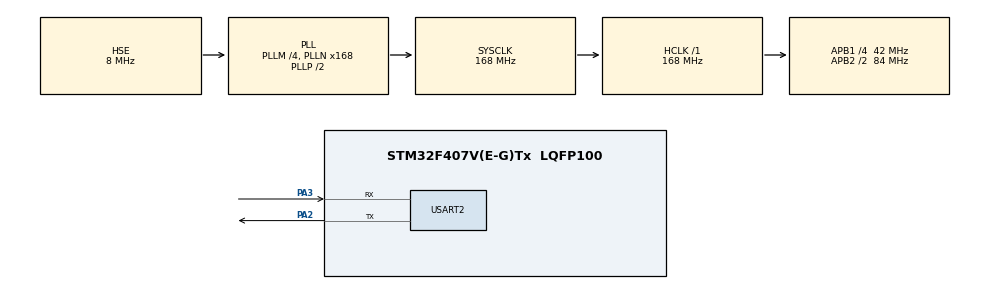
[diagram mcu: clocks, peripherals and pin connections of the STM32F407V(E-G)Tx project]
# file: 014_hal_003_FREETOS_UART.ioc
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FREERTOS.Tasks01=defaultTask,0,128,StartDefaultTask,Default,NULL,Dynamic,NULL,NULL;myTask02,0,128,StartTask02,Default,NULL,Dynamic,NULL,NULL
FREERTOS.configUSE_NEWLIB_REENTRANT=1
Mcu.Family=STM32F4
Mcu.Name=STM32F407V(E-G)Tx
Mcu.Package=LQFP100
NVIC.PriorityGroup=NVIC_PRIORITYGROUP_4
NVIC.TIM2_IRQn=true\:15\:0\:false\:false\:true\:false\:false\:true\:true
NVIC.TimeBase=TIM2_IRQn
NVIC.TimeBaseIP=TIM2
PA2.Mode=Asynchronous
PA2.Signal=USART2_TX
PA3.Mode=Asynchronous
PA3.Signal=USART2_RX
PH0-OSC_IN.Mode=HSE-External-Oscillator
PH0-OSC_IN.Signal=RCC_OSC_IN
PH1-OSC_OUT.Mode=HSE-External-Oscillator
PH1-OSC_OUT.Signal=RCC_OSC_OUT
ProjectManager.HeapSize=0x200
ProjectManager.StackSize=0x400
ProjectManager.TargetToolchain=STM32CubeIDE
RCC.48MHZClocksFreq_Value=84000000
RCC.AHBFreq_Value=168000000
RCC.APB1CLKDivider=RCC_HCLK_DIV4
RCC.APB1Freq_Value=42000000
RCC.APB1TimFreq_Value=84000000
RCC.APB2CLKDivider=RCC_HCLK_DIV2
RCC.APB2Freq_Value=84000000
RCC.APB2TimFreq_Value=168000000
RCC.CortexFreq_Value=168000000
RCC.HCLKFreq_Value=168000000
RCC.HSE_VALUE=8000000
RCC.HSI_VALUE=16000000
RCC.LSE_VALUE=32768
RCC.PLLM=4
RCC.PLLN=168
RCC.PLLSourceVirtual=RCC_PLLSOURCE_HSE
RCC.SYSCLKFreq_VALUE=168000000
RCC.SYSCLKSource=RCC_SYSCLKSOURCE_PLLCLK
RCC.VCOOutputFreq_Value=336000000
USART2.VirtualMode=VM_ASYNC
VP_FREERTOS_VS_CMSIS_V1.Mode=CMSIS_V1
VP_SYS_VS_tim2.Mode=TIM2
board=custom

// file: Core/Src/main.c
/* USER CODE BEGIN Header */
/**
  ******************************************************************************
  * @file           : main.c
  * @brief          : Main program body
  ******************************************************************************
  * @attention
  *
  * Copyright (c) 2023 STMicroelectronics.
  * All rights reserved.
  *
  * This software is licensed under terms that can be found in the LICENSE file
  * in the root directory of this software component.
  * If no LICENSE file comes with this software, it is provided AS-IS.
  *
  ******************************************************************************
  */
/* USER CODE END Header */
#include "main.h"
#include "cmsis_os.h"

UART_HandleTypeDef huart2;

osThreadId defaultTaskHandle;
osThreadId myTask02Handle;

/* USER CODE BEGIN PV */

osThreadId Task3Handle;

/* USER CODE END PV */

void SystemClock_Config(void);
static void MX_GPIO_Init(void);
static void MX_USART2_UART_Init(void);
void StartDefaultTask(void const * argument);
void StartTask02(void const * argument);

/* USER CODE BEGIN PFP */

void Task3_init(void const * argument);

/* USER CODE END PFP */

/* USER CODE BEGIN 0 */

void send_deftask(void){
	uint8_t data[]="hello from send_deftask.\n";
	HAL_UART_Transmit(&huart2, data, sizeof(data), 500);
}

void send_task2(void){
	uint8_t data[]="hello from send_task2.\n";
	HAL_UART_Transmit(&huart2, data, sizeof(data), 500);
}

void send_task3(void){
	uint8_t data[]="hello from send_task3.\n";
	HAL_UART_Transmit(&huart2, data, sizeof(data), 500);
}

/* USER CODE END 0 */

int main(void)
{

  /* MCU Configuration--------------------------------------------------------*/

  /* Reset of all peripherals, Initializes the Flash interface and the Systick. */
  HAL_Init();

  /* Configure the system clock */
  SystemClock_Config();

  /* Initialize all configured peripherals */
  MX_GPIO_Init();
  MX_USART2_UART_Init();

  /* Create the thread(s) */
  /* definition and creation of defaultTask */
  osThreadDef(defaultTask, StartDefaultTask, osPriorityNormal, 0, 128);
  defaultTaskHandle = osThreadCreate(osThread(defaultTask), NULL);

  /* definition and creation of myTask02 */
  osThreadDef(myTask02, StartTask02, osPriorityAboveNormal, 0, 128);
  myTask02Handle = osThreadCreate(osThread(myTask02), NULL);

  /* USER CODE BEGIN RTOS_THREADS */
  /* add threads, ... */

  osThreadDef(Task3,Task3_init,osPriorityBelowNormal,0,128);
  Task3Handle = osThreadCreate(osThread(Task3),NULL);

  /* USER CODE END RTOS_THREADS */

  /* Start scheduler */
  osKernelStart();
  /* We should never get here as control is now taken by the scheduler */
  /* Infinite loop */
  while (1)
  {

  }
}

void SystemClock_Config(void)
{
  RCC_OscInitTypeDef RCC_OscInitStruct = {0};
  RCC_ClkInitTypeDef RCC_ClkInitStruct = {0};

  /** Configure the main internal regulator output voltage
  */
  __HAL_RCC_PWR_CLK_ENABLE();
  __HAL_PWR_VOLTAGESCALING_CONFIG(PWR_REGULATOR_VOLTAGE_SCALE1);

  /** Initializes the RCC Oscillators according to the specified parameters
  * in the RCC_OscInitTypeDef structure.
  */
  RCC_OscInitStruct.OscillatorType = RCC_OSCILLATORTYPE_HSE;
  RCC_OscInitStruct.HSEState = RCC_HSE_ON;
  RCC_OscInitStruct.PLL.PLLState = RCC_PLL_ON;
  RCC_OscInitStruct.PLL.PLLSource = RCC_PLLSOURCE_HSE;
  RCC_OscInitStruct.PLL.PLLM = 4;
  RCC_OscInitStruct.PLL.PLLN = 168;
  RCC_OscInitStruct.PLL.PLLP = RCC_PLLP_DIV2;
  RCC_OscInitStruct.PLL.PLLQ = 4;
  if (HAL_RCC_OscConfig(&RCC_OscInitStruct) != HAL_OK)
  {
    Error_Handler();
  }

  /** Initializes the CPU, AHB and APB buses clocks
  */
  RCC_ClkInitStruct.ClockType = RCC_CLOCKTYPE_HCLK|RCC_CLOCKTYPE_SYSCLK
                              |RCC_CLOCKTYPE_PCLK1|RCC_CLOCKTYPE_PCLK2;
  RCC_ClkInitStruct.SYSCLKSource = RCC_SYSCLKSOURCE_PLLCLK;
  RCC_ClkInitStruct.AHBCLKDivider = RCC_SYSCLK_DIV1;
  RCC_ClkInitStruct.APB1CLKDivider = RCC_HCLK_DIV4;
  RCC_ClkInitStruct.APB2CLKDivider = RCC_HCLK_DIV2;

  if (HAL_RCC_ClockConfig(&RCC_ClkInitStruct, FLASH_LATENCY_5) != HAL_OK)
  {
    Error_Handler();
  }
}

static void MX_USART2_UART_Init(void)
{

  huart2.Instance = USART2;
  huart2.Init.BaudRate = 115200;
  huart2.Init.WordLength = UART_WORDLENGTH_8B;
  huart2.Init.StopBits = UART_STOPBITS_1;
  huart2.Init.Parity = UART_PARITY_NONE;
  huart2.Init.Mode = UART_MODE_TX_RX;
  huart2.Init.HwFlowCtl = UART_HWCONTROL_NONE;
  huart2.Init.OverSampling = UART_OVERSAMPLING_16;
  if (HAL_UART_Init(&huart2) != HAL_OK)
  {
    Error_Handler();
  }

}

static void MX_GPIO_Init(void)
{

  /* GPIO Ports Clock Enable */
  __HAL_RCC_GPIOH_CLK_ENABLE();
  __HAL_RCC_GPIOA_CLK_ENABLE();

}

void StartDefaultTask(void const * argument)
{
  /* USER CODE BEGIN 5 */
  /* Infinite loop */
  for(;;)
  {
    send_deftask();
    osDelay(1000);
  }
  /* USER CODE END 5 */
}

void StartTask02(void const * argument)
{
  /* USER CODE BEGIN StartTask02 */
  /* Infinite loop */
  for(;;)
  {
    send_task2();
    osDelay(1000); // 1sn
  }
  /* USER CODE END StartTask02 */
}

void Task3_init(void const *argument){
	while(1){
		send_task3();
		osDelay(1000);
	}
}

void HAL_TIM_PeriodElapsedCallback(TIM_HandleTypeDef *htim)
{
  if (htim->Instance == TIM2) {
    HAL_IncTick();
  }
}

void Error_Handler(void)
{
  __disable_irq();
  while (1)
  {
  }
}
